# f28p65x_cpu1_sys_regs register map
Vendor: Texas Instruments
Peripheral module from a debugger description file (folder C2000).
Address unit: 16 bits
Registers are 32-bit, read-write, no defined reset value unless marked. A register's access mark holds for its fields unless they carry their own. Offsets are as the file gives them; lines under a group give offsets from that group; [hi:lo] are bit positions; {n}, {i} and the like mark numbered series; 'fields as' and 'values as' point back to an identical list; <NAME> marks a mode.

## CPU1_SYS_REGS — CPU1 SYS Registers
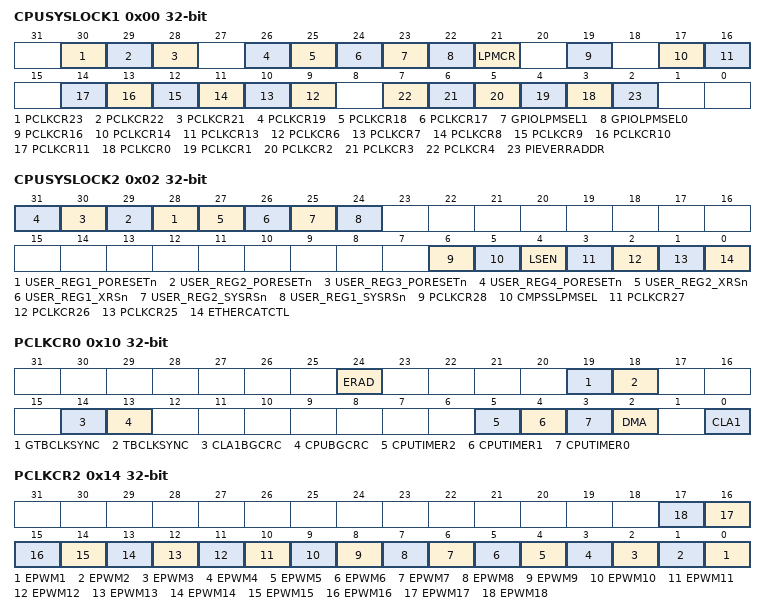
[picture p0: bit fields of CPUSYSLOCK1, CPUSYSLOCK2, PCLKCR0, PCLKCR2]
0x00 CPUSYSLOCK1 — Lock bit for CPUSYS registers
  [30] PCLKCR23 — Lock bit for PCLKCR23 Register
  [29] PCLKCR22 — Lock bit for PCLKCR22 Register
  [28] PCLKCR21 — Lock bit for PCLKCR21 Register
  [26] PCLKCR19 — Lock bit for PCLKCR19 Register
  [25] PCLKCR18 — Lock bit for PCLKCR18 Register
  [24] PCLKCR17 — Lock bit for PCLKCR17 Register
  [23] GPIOLPMSEL1 — Lock bit for GPIOLPMSEL1 Register
  [22] GPIOLPMSEL0 — Lock bit for GPIOLPMSEL0 Register
  [21] LPMCR — Lock bit for LPMCR Register
  [19] PCLKCR16 — Lock bit for PCLKCR16 Register
  [17] PCLKCR14 — Lock bit for PCLKCR14 Register
  [16] PCLKCR13 — Lock bit for PCLKCR13 Register
  [n+3] PCLKCR{n} (n=6..11) — Lock bit for PCLKCR{n} Register
  [n+3] PCLKCR{n} (n=0..4) — Lock bit for PCLKCR{n} Register
  [2] PIEVERRADDR — Lock bit for PIEVERRADDR Register
0x02 CPUSYSLOCK2 — Lock bit for CPUSYS registers
  [n+27] USER_REG{n}_PORESETn (n=1..4) — Lock bit for USER_REG{n}_PORESETn
  [27] USER_REG2_XRSn — Lock bit for USER_REG2_XRSn
  [26] USER_REG1_XRSn — Lock bit for USER_REG1_XRSn
  [25] USER_REG2_SYSRSn — Lock bit for USER_REG2_SYSRSn
  [24] USER_REG1_SYSRSn — Lock bit for USER_REG1_SYSRSn
  [6] PCLKCR28 — Lock bit for PCLKCR28 Register
  [5] CMPSSLPMSEL — Lock bit for CMPSSLPMSEL register
  [4] LSEN — Lock bit for LSEN Register
  [3] PCLKCR27 — Lock bit for PCLKCR27 Register
  [2] PCLKCR26 — Lock bit for PCLKCR26 Register
  [1] PCLKCR25 — Lock bit for PCLKCR25 Register
  [0] ETHERCATCTL — Lock bit for ETHERCATCTL register
0x0A PIEVERRADDR — PIE Vector Fetch Error Address register
  [21:0] ADDR — PIE Vector Fetch Error Handler Routine Address
0x0C ETHERCATCTL — ETHERCAT control register.
  [0] I2CLOOPBACK — Loopback I2C port of etherCAT IP to I2C_A.
0x10 PCLKCR0 — Peripheral Clock Gating Registers
  [24] ERAD — ERAD module clock enable
  [19] GTBCLKSYNC — EPWM Time Base Clock Global sync
  [18] TBCLKSYNC — EPWM Time Base Clock sync
  [14] CLA1BGCRC — CLA1BGCRC Clock Enable Bit
  [13] CPUBGCRC — CPUBGCRC Clock Enable Bit
  [5] CPUTIMER2 — CPUTIMER2 Clock Enable bit
  [4] CPUTIMER1 — CPUTIMER1 Clock Enable bit
  [3] CPUTIMER0 — CPUTIMER0 Clock Enable bit
  [2] DMA — DMA Clock Enable bit
  [0] CLA1 — CLA1 Clock Enable Bit
0x12 PCLKCR1 — Peripheral Clock Gating Register - EMIF
  [0] EMIF1 — EMIF1 Clock Enable bit
0x14 PCLKCR2 — Peripheral Clock Gating Register - ETPWM
  [n-1] EPWM{n} (n=1..18) — EPWM{n} Clock Enable bit
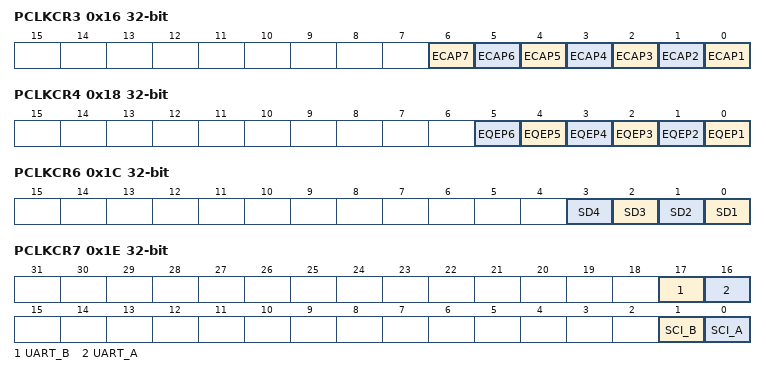
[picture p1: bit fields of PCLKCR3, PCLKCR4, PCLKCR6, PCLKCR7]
0x16 PCLKCR3 — Peripheral Clock Gating Register - ECAP
  [n-1] ECAP{n} (n=1..7) — ECAP{n} Clock Enable bit
0x18 PCLKCR4 — Peripheral Clock Gating Register - EQEP
  [n-1] EQEP{n} (n=1..6) — EQEP{n} Clock Enable bit
0x1C PCLKCR6 — Peripheral Clock Gating Register - SDFM
  [n-1] SD{n} (n=1..4) — SD{n} Clock Enable bit
0x1E PCLKCR7 — Peripheral Clock Gating Register - SCI, UART
  [17] UART_B — UART_B Clock Enable bit
  [16] UART_A — UART_A Clock Enable bit
  [1] SCI_B — SCI_B Clock Enable bit
  [0] SCI_A — SCI_A Clock Enable bit
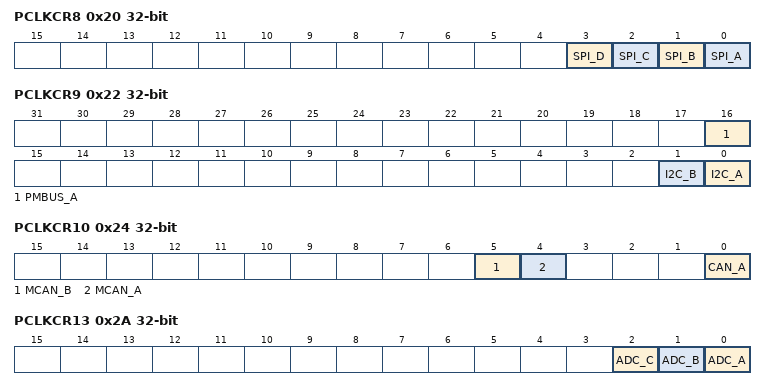
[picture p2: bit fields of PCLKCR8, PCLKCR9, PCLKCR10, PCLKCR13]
0x20 PCLKCR8 — Peripheral Clock Gating Register - SPI
  [3] SPI_D — SPI_D Clock Enable bit
  [2] SPI_C — SPI_C Clock Enable bit
  [1] SPI_B — SPI_B Clock Enable bit
  [0] SPI_A — SPI_A Clock Enable bit
0x22 PCLKCR9 — Peripheral Clock Gating Register - I2C, PMBUS
  [16] PMBUS_A — PMBUS_A Clock Enable bit
  [1] I2C_B — I2C_B Clock Enable bit
  [0] I2C_A — I2C_A Clock Enable bit
0x24 PCLKCR10 — Peripheral Clock Gating Register - CAN
  [5] MCAN_B — MCAN_B Clock Enable bit
  [4] MCAN_A — MCAN_A Clock Enable bit
  [0] CAN_A — CAN_A Clock Enable bit
0x26 PCLKCR11 — Peripheral Clock Gating Register - McBSP_USB
  [16] USB_A — USB_A Clock Enable bit
0x2A PCLKCR13 — Peripheral Clock Gating Register - ADC
  [2] ADC_C — ADC_C Clock Enable bit
  [1] ADC_B — ADC_B Clock Enable bit
  [0] ADC_A — ADC_A Clock Enable bit
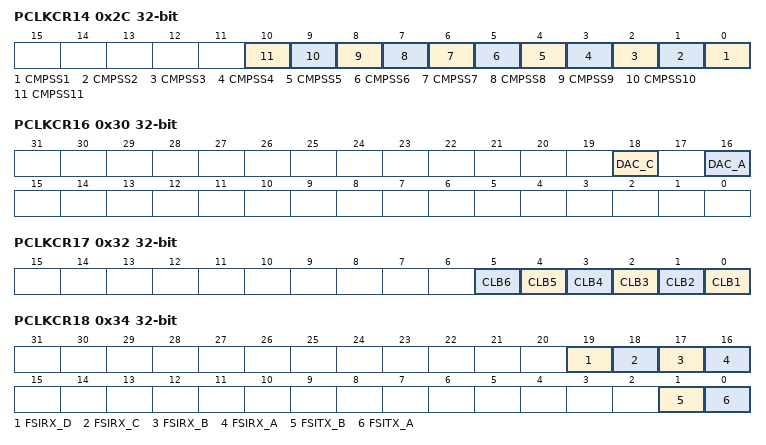
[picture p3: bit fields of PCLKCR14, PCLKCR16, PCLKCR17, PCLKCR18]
0x2C PCLKCR14 — Peripheral Clock Gating Register - CMPSS
  [n-1] CMPSS{n} (n=1..11) — CMPSS{n} Clock Enable bit
0x30 PCLKCR16 — Peripheral Clock Gating Register Buf_DAC
  [18] DAC_C — Buffered_DAC_C Clock Enable Bit
  [16] DAC_A — Buffered_DAC_A Clock Enable Bit
0x32 PCLKCR17 — Peripheral Clock Gating Register - CLB
  [n-1] CLB{n} (n=1..6) — CLB{n} Clock Enable bit
0x34 PCLKCR18 — Peripheral Clock Gating Register - FSI
  [19] FSIRX_D — FSIRX_C Clock Enable bit
  [18] FSIRX_C — FSITX_C Clock Enable bit
  [17] FSIRX_B — FSIRX_B Clock Enable bit
  [16] FSIRX_A — FSITX_B Clock Enable bit
  [1] FSITX_B — FSIRX_A Clock Enable bit
  [0] FSITX_A — FSITX_A Clock Enable bit
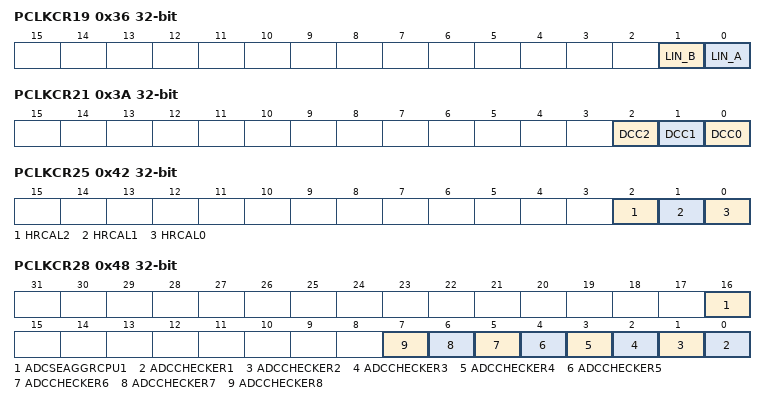
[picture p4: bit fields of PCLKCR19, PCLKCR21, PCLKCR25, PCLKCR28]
0x36 PCLKCR19 — Peripheral Clock Gating Register - LIN
  [1] LIN_B — LIN_B Clock Enable bit
  [0] LIN_A — LIN_A Clock Enable bit
0x3A PCLKCR21 — Peripheral Clock Gating Register - DCC
  [2] DCC2 — DCC2 Clock Enable Bit
  [1] DCC1 — DCC1 Clock Enable Bit
  [0] DCC0 — DCC0 Clock Enable Bit
0x3E PCLKCR23 — Peripheral Clock Gating Register - EtherCAT
  [0] ETHERCAT — ETHERCAT Clock Enable Bit
0x42 PCLKCR25 — Peripheral Clock Gating Register - HRCAL0,1,2
  [2] HRCAL2 — HRCAL2 Clock Enable Bit
  [1] HRCAL1 — HRCAL1 Clock Enable Bit
  [0] HRCAL0 — HRCAL0 Clock Enable Bit
0x44 PCLKCR26 — Peripheral Clock Gating Register - AES
  [0] AESA — AESA Clock Enable Bit
0x46 PCLKCR27 — Peripheral Clock Gating Register - EPG
  [0] EPG1 — EPG1 Clock Enable Bit
0x48 PCLKCR28 — Peripheral Clock Gating Register - ADCCHECKER
  [16] ADCSEAGGRCPU1 — ADCSEAGGRCPU1 Clock Enable bit
  [n-1] ADCCHECKER{n} (n=1..8) — ADCCHECKER{n} Clock Enable bit
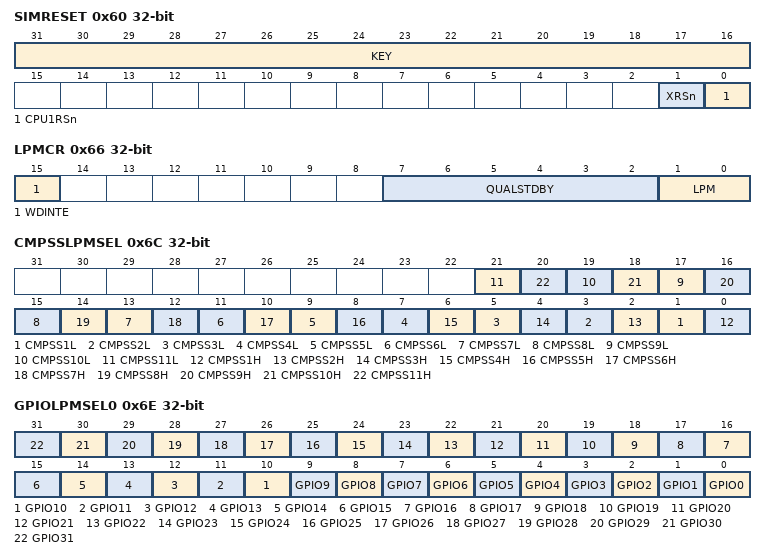
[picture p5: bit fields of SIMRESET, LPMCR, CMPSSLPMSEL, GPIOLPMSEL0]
0x60 SIMRESET — Simulated Reset Register
  [31:16] KEY — Key value to enable write
  [1] XRSn — Generates a simulated XRSn
  [0] CPU1RSn — Generates a reset to CPU
0x66 LPMCR — LPM Control Register
  [15] WDINTE — Enable for WDINT wakeup from STANDBY
  [7:2] QUALSTDBY — STANDBY Wakeup Pin Qualification Setting
  [1:0] LPM — Low Power Mode setting
0x68 CPUID ro — Indicates CPU1 or CPU2
  [1:0] CPUID
0x6C CMPSSLPMSEL — CMPSS LPM Wakeup select registers
  [2n-1] CMPSS{n}L (n=1..11) — CMPSS{n}L Enable for LPM Wakeup
  [2n-2] CMPSS{n}H (n=1..11) — CMPSS{n}H Enable for LPM Wakeup
0x6E GPIOLPMSEL0 — GPIO LPM Wakeup select registers
  [n] GPIO{n} (n=0..31) — GPIO{n} Enable for LPM Wakeup
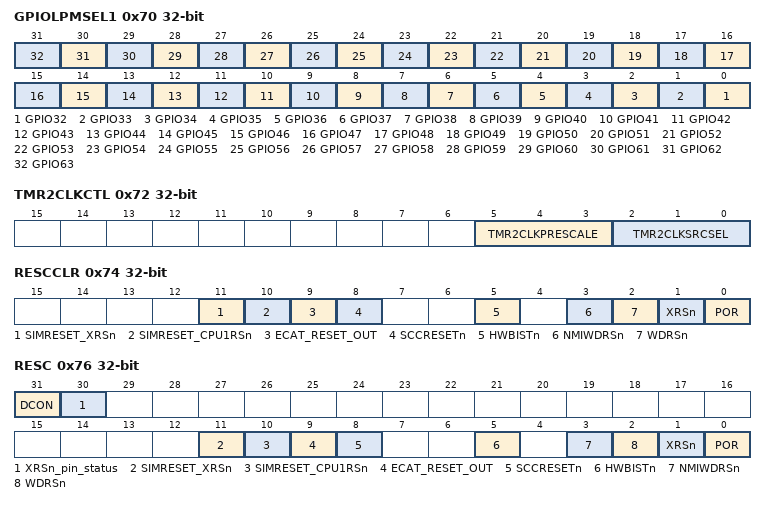
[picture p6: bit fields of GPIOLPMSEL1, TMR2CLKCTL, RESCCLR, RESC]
0x70 GPIOLPMSEL1 — GPIO LPM Wakeup select registers
  [n-32] GPIO{n} (n=32..63) — GPIO{n} Enable for LPM Wakeup
0x72 TMR2CLKCTL — Timer2 Clock Measurement functionality control register
  [5:3] TMR2CLKPRESCALE — CPU Timer 2 Clock Pre-Scale Value
  [2:0] TMR2CLKSRCSEL — CPU Timer 2 Clock Source Select Bit
0x74 RESCCLR — Reset Cause Clear Register
  [11] SIMRESET_XRSn — SIMRESET_XRSn Reset Cause Indication Bit
  [10] SIMRESET_CPU1RSn — SIMRESET_CPU1RSn Reset Cause Indication Bit
  [9] ECAT_RESET_OUT — ECAT_RESET_OUT Reset Cause Indication Bit
  [8] SCCRESETn — SCCRESETn Reset Cause Indication Bit
  [5] HWBISTn — HWBISTn Reset Cause Indication Bit
  [3] NMIWDRSn — NMIWDRSn Reset Cause Indication Bit
  [2] WDRSn — WDRSn Reset Cause Indication Bit
  [1] XRSn — XRSn Reset Cause Indication Bit
  [0] POR — POR Reset Cause Indication Bit
0x76 RESC ro — Reset Cause register
  [31] DCON — Debugger conntion status to C28x
  [30] XRSn_pin_status
  [11] SIMRESET_XRSn — SIMRESET_XRSn Reset Cause Indication Bit
  [10] SIMRESET_CPU1RSn — SIMRESET_CPU1RSn Reset Cause Indication Bit
  [9] ECAT_RESET_OUT — ECAT_RESET_OUT Reset Cause Indication Bit
  [8] SCCRESETn — SCCRESETn Reset Cause Indication Bit
  [5] HWBISTn — HWBISTn Reset Cause Indication Bit
  [3] NMIWDRSn — NMIWDRSn Reset Cause Indication Bit
  [2] WDRSn — WDRSn Reset Cause Indication Bit
  [1] XRSn — XRSn Reset Cause Indication Bit
  [0] POR — POR Reset Cause Indication Bit
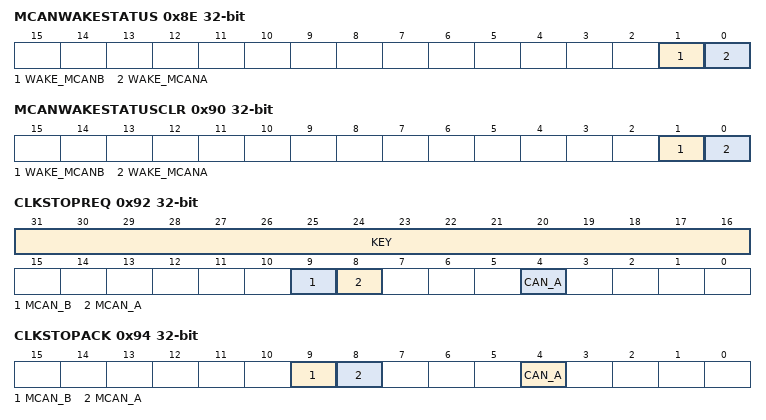
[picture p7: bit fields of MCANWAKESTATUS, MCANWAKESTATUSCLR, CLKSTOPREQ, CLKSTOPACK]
0x8E MCANWAKESTATUS ro
  [1] WAKE_MCANB — MCANB Wake Status
  [0] WAKE_MCANA — MCANA Wake Status
0x90 MCANWAKESTATUSCLR — MCAN Wake Status Clear Register
  [1] WAKE_MCANB — Cear bit for MCANWAKESTATUS.WAKE_MCANB bit
  [0] WAKE_MCANA — Cear bit for MCANWAKESTATUS.WAKE_MCANA bit
0x92 CLKSTOPREQ — Peripheral Clock Stop Request Register
  [31:16] KEY — Key for register write
  [9] MCAN_B — MCAN_B Clock Stop Request Bit
  [8] MCAN_A — MCAN_A Clock Stop Request Bit
  [4] CAN_A — CAN_A Clock Stop Request Bit
0x94 CLKSTOPACK ro — Peripheral Clock Stop Ackonwledge Register
  [9] MCAN_B — MCAN_B Clock Stop Ack Bit
  [8] MCAN_A — MCAN_A Clock Stop Ack Bit
  [4] CAN_A — CAN_A Clock Stop Ack Bit
0x96 USER_REG1_SYSRSn — Software Configurable registers reset by SYSRSn
  [31:0] BITS — SW configurable bits
0x98 USER_REG2_SYSRSn — Software Configurable registers reset by SYSRSn
  [31:0] BITS — SW configurable bits
0x9A USER_REG1_XRSn — Software Configurable registers reset by XRSn
  [31:0] BITS — SW configurable bits
0x9C USER_REG2_XRSn — Software Configurable registers reset by XRSn
  [31:0] BITS — SW configurable bits
{0x9C+2i} USER_REG{i}_PORESETn (i=1..4) — Software Configurable registers reset by PORESETn
  [31:0] BITS — SW configurable bits
0xA6 JTAG_MMR_REG access not given — Readback of JTAG registers for test purpose
